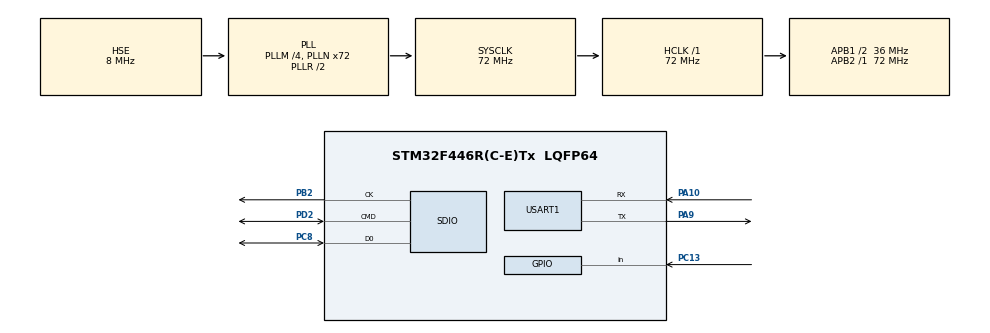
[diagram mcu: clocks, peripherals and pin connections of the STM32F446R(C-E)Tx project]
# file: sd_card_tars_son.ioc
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Dma.Request0=SDIO_RX
Dma.Request1=SDIO_TX
Dma.SDIO_RX.0.Direction=DMA_PERIPH_TO_MEMORY
Dma.SDIO_RX.0.FIFOMode=DMA_FIFOMODE_ENABLE
Dma.SDIO_RX.0.FIFOThreshold=DMA_FIFO_THRESHOLD_FULL
Dma.SDIO_RX.0.Instance=DMA2_Stream3
Dma.SDIO_RX.0.MemBurst=DMA_MBURST_INC4
Dma.SDIO_RX.0.MemDataAlignment=DMA_MDATAALIGN_WORD
Dma.SDIO_RX.0.MemInc=DMA_MINC_ENABLE
Dma.SDIO_RX.0.Mode=DMA_PFCTRL
Dma.SDIO_RX.0.PeriphBurst=DMA_PBURST_INC4
Dma.SDIO_RX.0.PeriphDataAlignment=DMA_PDATAALIGN_WORD
Dma.SDIO_RX.0.PeriphInc=DMA_PINC_DISABLE
Dma.SDIO_RX.0.Priority=DMA_PRIORITY_LOW
Dma.SDIO_TX.1.Direction=DMA_MEMORY_TO_PERIPH
Dma.SDIO_TX.1.FIFOMode=DMA_FIFOMODE_ENABLE
Dma.SDIO_TX.1.FIFOThreshold=DMA_FIFO_THRESHOLD_FULL
Dma.SDIO_TX.1.Instance=DMA2_Stream6
Dma.SDIO_TX.1.MemBurst=DMA_MBURST_INC4
Dma.SDIO_TX.1.MemDataAlignment=DMA_MDATAALIGN_WORD
Dma.SDIO_TX.1.MemInc=DMA_MINC_ENABLE
Dma.SDIO_TX.1.Mode=DMA_PFCTRL
Dma.SDIO_TX.1.PeriphBurst=DMA_PBURST_INC4
Dma.SDIO_TX.1.PeriphDataAlignment=DMA_PDATAALIGN_WORD
Dma.SDIO_TX.1.PeriphInc=DMA_PINC_DISABLE
Dma.SDIO_TX.1.Priority=DMA_PRIORITY_LOW
FATFS.BSP.number=1
FATFS.USE_DMA_CODE_SD=1
FATFS._MAX_SS=4096
FATFS._USE_FIND=0
FATFS0.BSP.STBoard=false
FATFS0.BSP.api=Unknown
FATFS0.BSP.instance=PC13
FATFS0.BSP.ip=GPIO
FATFS0.BSP.mode=Input
FATFS0.BSP.name=Detect_SDIO
FATFS0.BSP.solution=PC13
Mcu.Family=STM32F4
Mcu.Name=STM32F446R(C-E)Tx
Mcu.Package=LQFP64
NVIC.DMA2_Stream3_IRQn=true\:0\:0\:false\:false\:true\:false\:true\:true
NVIC.DMA2_Stream6_IRQn=true\:0\:0\:false\:false\:true\:false\:true\:true
NVIC.PriorityGroup=NVIC_PRIORITYGROUP_4
NVIC.SDIO_IRQn=true\:0\:0\:false\:false\:true\:true\:true\:true
NVIC.USART1_IRQn=true\:0\:0\:false\:false\:true\:true\:true\:true
PA10.Mode=Asynchronous
PA10.Signal=USART1_RX
PA13.Mode=Serial_Wire
PA13.Signal=SYS_JTMS-SWDIO
PA14.Mode=Serial_Wire
PA14.Signal=SYS_JTCK-SWCLK
PA9.Mode=Asynchronous
PA9.Signal=USART1_TX
PB2.Mode=SD_1_bit
PB2.Signal=SDIO_CK
PC13.GPIO_PuPd=GPIO_PULLDOWN
PC13.Signal=GPIO_Input
PC8.GPIO_PuPd=GPIO_NOPULL
PC8.Mode=SD_1_bit
PC8.Signal=SDIO_D0
PD2.GPIO_PuPd=GPIO_NOPULL
PD2.Mode=SD_1_bit
PD2.Signal=SDIO_CMD
PH0-OSC_IN.Mode=HSE-External-Oscillator
PH0-OSC_IN.Signal=RCC_OSC_IN
PH1-OSC_OUT.Mode=HSE-External-Oscillator
PH1-OSC_OUT.Signal=RCC_OSC_OUT
ProjectManager.HeapSize=0x200
ProjectManager.StackSize=0x400
ProjectManager.TargetToolchain=STM32CubeIDE
RCC.AHBFreq_Value=72000000
RCC.APB1CLKDivider=RCC_HCLK_DIV2
RCC.APB1Freq_Value=36000000
RCC.APB1TimFreq_Value=72000000
RCC.APB2Freq_Value=72000000
RCC.APB2TimFreq_Value=72000000
RCC.CortexFreq_Value=72000000
RCC.HCLKFreq_Value=72000000
RCC.HSE_VALUE=8000000
RCC.PLLM=4
RCC.PLLN=72
RCC.PLLQ=3
RCC.PLLSourceVirtual=RCC_PLLSOURCE_HSE
RCC.SYSCLKFreq_VALUE=72000000
RCC.SYSCLKSource=RCC_SYSCLKSOURCE_PLLRCLK
RCC.USBFreq_Value=48000000
RCC.VCOOutputFreq_Value=144000000
SDIO.ClockDiv=4
USART1.VirtualMode=VM_ASYNC
VP_FATFS_VS_SDIO.Mode=SDIO
board=custom

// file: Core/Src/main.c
/* USER CODE BEGIN Header */
/**
  ******************************************************************************
  * @file           : main.c
  * @brief          : Main program body
  ******************************************************************************
  * @attention
  *
  * <h2><center>&copy; Copyright (c) 2020 STMicroelectronics.
  * All rights reserved.</center></h2>
  *
  * This software component is licensed by ST under BSD 3-Clause license,
  * the "License"; You may not use this file except in compliance with the
  * License. You may obtain a copy of the License at:
  *                        opensource.org/licenses/BSD-3-Clause
  *
  ******************************************************************************
  */
/* USER CODE END Header */
#include "main.h"
#include "fatfs.h"

/* USER CODE BEGIN Includes */
#include "File_Handling.h"
/* USER CODE END Includes */

SD_HandleTypeDef hsd;
DMA_HandleTypeDef hdma_sdio_rx;
DMA_HandleTypeDef hdma_sdio_tx;

UART_HandleTypeDef huart1;

void SystemClock_Config(void);
static void MX_GPIO_Init(void);
static void MX_DMA_Init(void);
static void MX_SDIO_SD_Init(void);
static void MX_USART1_UART_Init(void);

/* USER CODE BEGIN 0 */
char buffer[100];
int indx = 0;
/* USER CODE END 0 */

int main(void)
{

  /* MCU Configuration--------------------------------------------------------*/

  /* Reset of all peripherals, Initializes the Flash interface and the Systick. */
  HAL_Init();

  /* Configure the system clock */
  SystemClock_Config();

  /* Initialize all configured peripherals */
  MX_GPIO_Init();
  MX_DMA_Init();
  MX_SDIO_SD_Init();
  MX_FATFS_Init();
  MX_USART1_UART_Init();
  /* USER CODE BEGIN 2 */

  Mount_SD("/");
  Format_SD();
  Create_File("FILE1.TXT");

  /* USER CODE END 2 */

  /* Infinite loop */
  while (1)
  {

    /* USER CODE BEGIN 3 */

	sprintf(buffer, "berattan SD'ye---> %d\n", indx);
	Update_File("FILE1.TXT", buffer);

	indx++;

	HAL_Delay(2000);
  }
  /* USER CODE END 3 */
}

void SystemClock_Config(void)
{
  RCC_OscInitTypeDef RCC_OscInitStruct = {0};
  RCC_ClkInitTypeDef RCC_ClkInitStruct = {0};

  /** Configure the main internal regulator output voltage
  */
  __HAL_RCC_PWR_CLK_ENABLE();
  __HAL_PWR_VOLTAGESCALING_CONFIG(PWR_REGULATOR_VOLTAGE_SCALE3);

  /** Initializes the RCC Oscillators according to the specified parameters
  * in the RCC_OscInitTypeDef structure.
  */
  RCC_OscInitStruct.OscillatorType = RCC_OSCILLATORTYPE_HSE;
  RCC_OscInitStruct.HSEState = RCC_HSE_ON;
  RCC_OscInitStruct.PLL.PLLState = RCC_PLL_ON;
  RCC_OscInitStruct.PLL.PLLSource = RCC_PLLSOURCE_HSE;
  RCC_OscInitStruct.PLL.PLLM = 4;
  RCC_OscInitStruct.PLL.PLLN = 72;
  RCC_OscInitStruct.PLL.PLLP = RCC_PLLP_DIV2;
  RCC_OscInitStruct.PLL.PLLQ = 3;
  RCC_OscInitStruct.PLL.PLLR = 2;
  if (HAL_RCC_OscConfig(&RCC_OscInitStruct) != HAL_OK)
  {
    Error_Handler();
  }

  /** Initializes the CPU, AHB and APB buses clocks
  */
  RCC_ClkInitStruct.ClockType = RCC_CLOCKTYPE_HCLK|RCC_CLOCKTYPE_SYSCLK
                              |RCC_CLOCKTYPE_PCLK1|RCC_CLOCKTYPE_PCLK2;
  RCC_ClkInitStruct.SYSCLKSource = RCC_SYSCLKSOURCE_PLLRCLK;
  RCC_ClkInitStruct.AHBCLKDivider = RCC_SYSCLK_DIV1;
  RCC_ClkInitStruct.APB1CLKDivider = RCC_HCLK_DIV2;
  RCC_ClkInitStruct.APB2CLKDivider = RCC_HCLK_DIV1;

  if (HAL_RCC_ClockConfig(&RCC_ClkInitStruct, FLASH_LATENCY_2) != HAL_OK)
  {
    Error_Handler();
  }
}

static void MX_SDIO_SD_Init(void)
{

  hsd.Instance = SDIO;
  hsd.Init.ClockEdge = SDIO_CLOCK_EDGE_RISING;
  hsd.Init.ClockBypass = SDIO_CLOCK_BYPASS_DISABLE;
  hsd.Init.ClockPowerSave = SDIO_CLOCK_POWER_SAVE_DISABLE;
  hsd.Init.BusWide = SDIO_BUS_WIDE_1B;
  hsd.Init.HardwareFlowControl = SDIO_HARDWARE_FLOW_CONTROL_DISABLE;
  hsd.Init.ClockDiv = 4;

}

static void MX_USART1_UART_Init(void)
{

  huart1.Instance = USART1;
  huart1.Init.BaudRate = 115200;
  huart1.Init.WordLength = UART_WORDLENGTH_8B;
  huart1.Init.StopBits = UART_STOPBITS_1;
  huart1.Init.Parity = UART_PARITY_NONE;
  huart1.Init.Mode = UART_MODE_TX_RX;
  huart1.Init.HwFlowCtl = UART_HWCONTROL_NONE;
  huart1.Init.OverSampling = UART_OVERSAMPLING_16;
  if (HAL_UART_Init(&huart1) != HAL_OK)
  {
    Error_Handler();
  }

}

static void MX_DMA_Init(void)
{

  /* DMA controller clock enable */
  __HAL_RCC_DMA2_CLK_ENABLE();

  /* DMA interrupt init */
  /* DMA2_Stream3_IRQn interrupt configuration */
  HAL_NVIC_SetPriority(DMA2_Stream3_IRQn, 0, 0);
  HAL_NVIC_EnableIRQ(DMA2_Stream3_IRQn);
  /* DMA2_Stream6_IRQn interrupt configuration */
  HAL_NVIC_SetPriority(DMA2_Stream6_IRQn, 0, 0);
  HAL_NVIC_EnableIRQ(DMA2_Stream6_IRQn);

}

static void MX_GPIO_Init(void)
{
  GPIO_InitTypeDef GPIO_InitStruct = {0};

  /* GPIO Ports Clock Enable */
  __HAL_RCC_GPIOC_CLK_ENABLE();
  __HAL_RCC_GPIOH_CLK_ENABLE();
  __HAL_RCC_GPIOB_CLK_ENABLE();
  __HAL_RCC_GPIOA_CLK_ENABLE();
  __HAL_RCC_GPIOD_CLK_ENABLE();

  /*Configure GPIO pin : PC13 */
  GPIO_InitStruct.Pin = GPIO_PIN_13;
  GPIO_InitStruct.Mode = GPIO_MODE_INPUT;
  GPIO_InitStruct.Pull = GPIO_PULLDOWN;
  HAL_GPIO_Init(GPIOC, &GPIO_InitStruct);

}

void Error_Handler(void)
{
}
